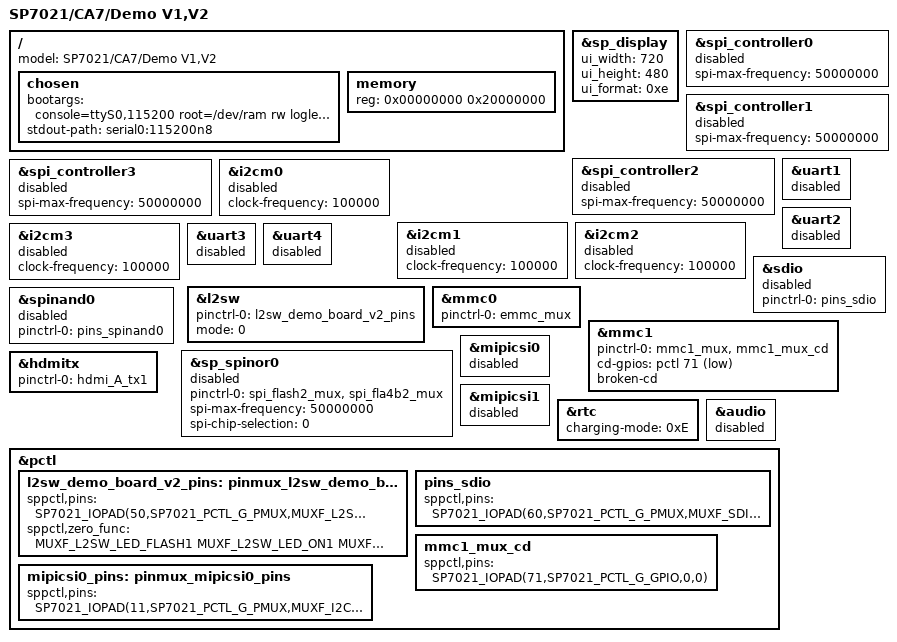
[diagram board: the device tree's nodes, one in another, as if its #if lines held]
/dts-v1/;

#include "sp7021-common.dtsi"

/ {
#ifdef CONFIG_MACH_PENTAGRAM_SP7021_ACHIP
	model = "SP7021/CA7/Demo V1,V2";
#else
	model = "SP7021/ARM926/Demo V1,V2";
#endif

	chosen {
		bootargs = "console=ttyS0,115200 root=/dev/ram rw loglevel=8 earlyprintk";
		stdout-path = "serial0:115200n8";
	};

	memory {
		reg = <0x00000000 0x20000000>; /* 512MB */
	};
};

&sp_display {
	ui_width = <720>;
	ui_height = <480>;
	ui_format = <0xe>;
		/* 0x2 = 8bpp (ARGB)
		 * 0x4 = YUY2
		 * 0x8 = RGB565
		 * 0x9 = ARGB1555
		 * 0xa = RGBA4444
		 * 0xb = ARGB4444
		 * 0xd = RGBA8888
		 * 0xe = ARGB8888 */
};

&spi_controller0 {
	spi-max-frequency = <50000000>;
	status = "disabled";
};

&spi_controller1 {
	spi-max-frequency = <50000000>;
	status = "disabled";
};

&spi_controller2 {
	spi-max-frequency = <50000000>;
	status = "disabled";
};

&spi_controller3 {
	spi-max-frequency = <50000000>;
	status = "disabled";
};

&i2cm0 {
	clock-frequency = <100000>;
	status = "disabled";
};

&i2cm1 {
	clock-frequency = <100000>;
	status = "disabled";
};

&i2cm2 {
	clock-frequency = <100000>;
	status = "disabled";
};

&i2cm3 {
	clock-frequency = <100000>;
	status = "disabled";
};

&uart1 {
	status = "disabled";
};

&uart2 {
	status = "disabled";
};

&uart3 {
	status = "disabled";
};

&uart4 {
	status = "disabled";
};

&sdio {
	pinctrl-names = "default";
	pinctrl-0 = <&pins_sdio>;
	status = "disabled";
};

&l2sw {
	pinctrl-names = "default";
	pinctrl-0 = <&l2sw_demo_board_v2_pins>;
	mode = < 0 >;
		/* 0 = daisy-chain mode
		 * 1 = dual NIC mode
		 * 2 = daisy-chain mode (disable SA learning) */
};

&mmc0 {
	pinctrl-names = "default";
	pinctrl-0 = <&emmc_mux>;
};

&mmc1 {
	pinctrl-names = "default";
	pinctrl-0 = <&mmc1_mux &mmc1_mux_cd>;
	cd-gpios = <&pctl 71 GPIO_ACTIVE_LOW>;
	broken-cd;
};

&spinand0 {
	pinctrl-names = "default";
	pinctrl-0 = <&pins_spinand0>;
	status = "disabled";
};

&sp_spinor0 {
	pinctrl-names = "default";
	pinctrl-0 = <&spi_flash2_mux &spi_fla4b2_mux>;
	spi-max-frequency = <50000000>;
	spi-chip-selection = <0>;
	status = "disabled";
};

&hdmitx {
	pinctrl-names = "default";
	pinctrl-0 = <&hdmi_A_tx1>;
};

&mipicsi0 {
	status = "disabled";
};

&mipicsi1 {
	status = "disabled";
};

&rtc {
	charging-mode = <0xE>;
	/*
	 *      0xE     Disable
	 *      0x1     0.86mA (2K Ohm with diode)
	 *      0x5     1.81mA (250 Ohm with diode)
	 *      0x9     2.07mA (50 Ohm with diode)
	 *      0xD     16.0mA (0 Ohm with diode)
	 *      0x3     1.36mA (2K Ohm without diode)
	 *      0x7     3.99mA (250 Ohm without diode)
	 *      0xB     4.41mA (50 Ohm without diode)
	 *      0xF     16.0mA (0 Ohm without diode)    */
};

&audio {
	status = "disabled";
};

&pctl {
	pinctrl-names = "default";

	l2sw_demo_board_v2_pins: pinmux_l2sw_demo_board_v2_pins {
		sppctl,pins = <
			SP7021_IOPAD(50,SP7021_PCTL_G_PMUX,MUXF_L2SW_CLK_OUT,0)
			SP7021_IOPAD(44,SP7021_PCTL_G_PMUX,MUXF_L2SW_MAC_SMI_MDC,0)
			SP7021_IOPAD(54,SP7021_PCTL_G_PMUX,MUXF_L2SW_LED_FLASH0,0)
			SP7021_IOPAD(45,SP7021_PCTL_G_PMUX,MUXF_L2SW_LED_ON0,0)
			SP7021_IOPAD(43,SP7021_PCTL_G_PMUX,MUXF_L2SW_MAC_SMI_MDIO,0)
			SP7021_IOPAD(53,SP7021_PCTL_G_PMUX,MUXF_L2SW_P0_MAC_RMII_TXEN,0)
			SP7021_IOPAD(51,SP7021_PCTL_G_PMUX,MUXF_L2SW_P0_MAC_RMII_TXD0,0)
			SP7021_IOPAD(52,SP7021_PCTL_G_PMUX,MUXF_L2SW_P0_MAC_RMII_TXD1,0)
			SP7021_IOPAD(47,SP7021_PCTL_G_PMUX,MUXF_L2SW_P0_MAC_RMII_CRSDV,0)
			SP7021_IOPAD(48,SP7021_PCTL_G_PMUX,MUXF_L2SW_P0_MAC_RMII_RXD0,0)
			SP7021_IOPAD(49,SP7021_PCTL_G_PMUX,MUXF_L2SW_P0_MAC_RMII_RXD1,0)
			SP7021_IOPAD(46,SP7021_PCTL_G_PMUX,MUXF_L2SW_P0_MAC_RMII_RXER,0)
		>;
		sppctl,zero_func = <
			MUXF_L2SW_LED_FLASH1
			MUXF_L2SW_LED_ON1
			MUXF_L2SW_P1_MAC_RMII_TXEN
			MUXF_L2SW_P1_MAC_RMII_TXD0
			MUXF_L2SW_P1_MAC_RMII_TXD1
			MUXF_L2SW_P1_MAC_RMII_CRSDV
			MUXF_L2SW_P1_MAC_RMII_RXD0
			MUXF_L2SW_P1_MAC_RMII_RXD1
			MUXF_L2SW_P1_MAC_RMII_RXER
			MUXF_DAISY_MODE
		>;
	};

	// SDIO for RTL8189ETV
	pins_sdio: pins_sdio {
		sppctl,pins = <
			SP7021_IOPAD(60,SP7021_PCTL_G_PMUX,MUXF_SDIO_D1,0)
			SP7021_IOPAD(58,SP7021_PCTL_G_PMUX,MUXF_SDIO_D0,0)
			SP7021_IOPAD(57,SP7021_PCTL_G_PMUX,MUXF_SDIO_CLK,0)
			SP7021_IOPAD(62,SP7021_PCTL_G_PMUX,MUXF_SDIO_CMD,0)
			SP7021_IOPAD(64,SP7021_PCTL_G_PMUX,MUXF_SDIO_D3,0)
			SP7021_IOPAD(59,SP7021_PCTL_G_PMUX,MUXF_SDIO_D2,0)
		>;
	};

	mmc1_mux_cd: mmc1_mux_cd {
		sppctl,pins = < SP7021_IOPAD(71,SP7021_PCTL_G_GPIO,0,0) >;
	};

	mipicsi0_pins: pinmux_mipicsi0_pins {
		sppctl,pins = <
			SP7021_IOPAD(11,SP7021_PCTL_G_PMUX,MUXF_I2CM1_DAT,0)
			SP7021_IOPAD(12,SP7021_PCTL_G_PMUX,MUXF_I2CM1_CLK,0)
		>;
	};
};
